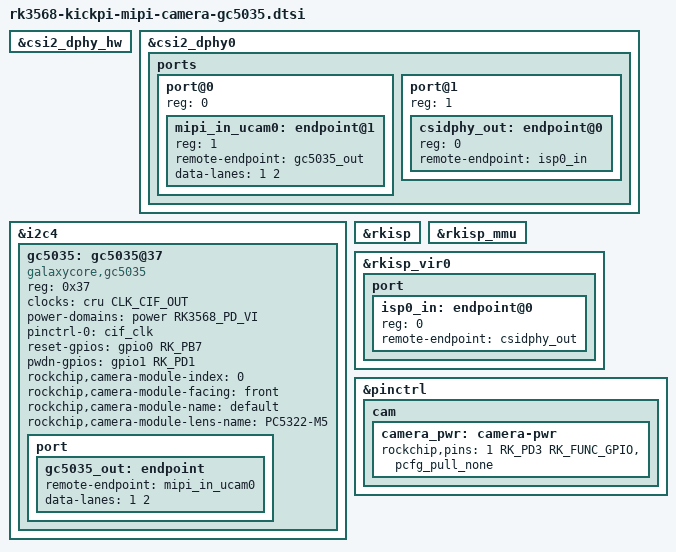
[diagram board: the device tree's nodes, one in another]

&csi2_dphy_hw {
    status = "okay";
};

&csi2_dphy0 {
    status = "okay";

    ports {
        #address-cells = <1>;
        #size-cells = <0>;
        port@0 {
            reg = <0>;
            #address-cells = <1>;
            #size-cells = <0>;

            mipi_in_ucam0: endpoint@1 {
                reg = <1>;
                remote-endpoint = <&gc5035_out>;
                data-lanes = <1 2>;
            };
        };
        port@1 {
            reg = <1>;
            #address-cells = <1>;
            #size-cells = <0>;

            csidphy_out: endpoint@0 {
                reg = <0>;
                remote-endpoint = <&isp0_in>;
            };
        };
    };
};

&i2c4 {
	status = "okay";
	gc5035: gc5035@37 {
		compatible = "galaxycore,gc5035";
		status = "okay";
		reg = <0x37>;
		clocks = <&cru CLK_CIF_OUT>;
		clock-names = "xvclk";
		power-domains = <&power RK3568_PD_VI>;
		pinctrl-names = "default";
		pinctrl-0 = <&cif_clk>;

		//reset pin control by hardware,used this pin switch to mipi input
		//0->FRONT camera, 1->REAR camera
		reset-gpios = <&gpio0 RK_PB7 GPIO_ACTIVE_HIGH>;
		pwdn-gpios = <&gpio1 RK_PD1 GPIO_ACTIVE_HIGH>;
		rockchip,camera-module-index = <0>;
		rockchip,camera-module-facing = "front";
		rockchip,camera-module-name = "default";
		rockchip,camera-module-lens-name = "PC5322-M5";
		port {
			gc5035_out: endpoint {
				remote-endpoint = <&mipi_in_ucam0>;
				data-lanes = <1 2>;
			};
		};
	};
};


&rkisp {
	status = "okay";
};

&rkisp_mmu {
	status = "okay";
};

&rkisp_vir0 {
	status = "okay";

	port {
		#address-cells = <1>;
		#size-cells = <0>;

		isp0_in: endpoint@0 {
			reg = <0>;
			remote-endpoint = <&csidphy_out>;
		};
	};
};

&pinctrl {
	cam {
		camera_pwr: camera-pwr {
			rockchip,pins =
				/* camera power en */
				<1 RK_PD3 RK_FUNC_GPIO &pcfg_pull_none>;
		};
	};
};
